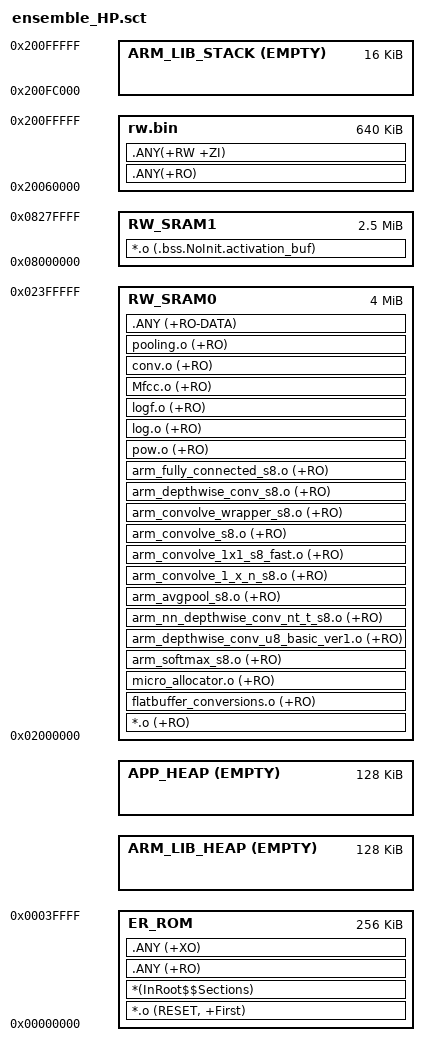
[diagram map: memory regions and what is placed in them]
#! armclang -E --target=arm-arm-none-eabi -mcpu=cortex-m55 -xc
; command above MUST be in first line (no comment above!)
/*
;-------- <<< Use Configuration Wizard in Context Menu >>> -------------------
*/

/*--------------------- ITCM Configuration ----------------------------------
; <h> ITCM Configuration
;   <o0> ITCM Base Address <0x0-0xFFFFFFFF:8>
;   <o1> ITCM Size (in Bytes) <0x0-0xFFFFFFFF:8>
; </h>
 *----------------------------------------------------------------------------*/
/* SRAM2 is mapped as ITCM in M55-HP */
#define __ROM_BASE      0x00000000
#define __ROM_SIZE      0x00040000

/*--------------------- DTCM Configuration ---------------------------
; <h> DTCM Configuration
;   <o0> DTCM Base Address    <0x0-0xFFFFFFFF:8>
;   <o1> DTCM Size (in Bytes) <0x0-0xFFFFFFFF:8>
; </h>
 *----------------------------------------------------------------------------*/
/* SRAM3 is mapped as DTCM in M55-HP */
#define __RAM_BASE      0x20000000
#define __RAM_SIZE      0x00100000

/*--------------------- Stack / Heap Configuration ---------------------------
; <h> Stack / Heap Configuration
;   <o0> Stack Size (in Bytes) <0x0-0xFFFFFFFF:8>
;   <o1> Heap Size (in Bytes) <0x0-0xFFFFFFFF:8>
;   <o2> App Heap Size (in Bytes) <0x0-0xFFFFFFFF:8>
; </h>
 *----------------------------------------------------------------------------*/
#define __STACK_SIZE    0x00004000
#define __HEAP_SIZE     0x00020000
#define __APP_HEAP_SIZE 0x00020000

/*
;------------- <<< end of configuration section >>> ---------------------------
*/


/*----------------------------------------------------------------------------
   User Stack & Heap boundary definition
   *----------------------------------------------------------------------------*/
#define __STACK_TOP     (__RAM_BASE + __RAM_SIZE)    /* starts at end of RAM */
#define __HEAP_BASE     (AlignExpr(+0, 8))           /* starts after RW_RAM section, 8 byte aligned */
#define __APP_HEAP_BASE (AlignExpr(+0, 8)) 	     /* starts after HEAP, 8 byte aligned */


/*----------------------------------------------------------------------------
  Scatter File Definitions definition
 *----------------------------------------------------------------------------*/
#define __RO_BASE       __ROM_BASE
#define __RO_SIZE       __ROM_SIZE

#define __RW_BASE       __RAM_BASE
#define __RW_SIZE      (__RAM_SIZE - __STACK_SIZE - __HEAP_SIZE - __APP_HEAP_SIZE)


LR_ROM __RO_BASE __RO_SIZE  {                       ; load region size_region
  ER_ROM __RO_BASE __RO_SIZE  {                     ; load address = execution address
   *.o (RESET, +First)
   *(InRoot$$Sections)
   .ANY (+RO)
   .ANY (+XO)
  }


#if __HEAP_SIZE > 0
  ARM_LIB_HEAP  __HEAP_BASE EMPTY  __HEAP_SIZE  {   ; Reserve empty region for heap
  }
#endif

  APP_HEAP  __APP_HEAP_BASE EMPTY  __APP_HEAP_SIZE {; Reserve empty region for application heap
  }



  ARM_LIB_STACK __STACK_TOP EMPTY -__STACK_SIZE {   ; Reserve empty region for stack
  }
}

 LOAD_REGION_1       0x02000000                  0x00400000
{ 
  RW_SRAM0 0x02000000 0x00400000  {  ; Update sections as needed
          ; nn model's baked in input matrices
        ;*.o (ifm)

        ; nn model
        ;*.o (nn_model)

        ; if the activation buffer (tensor arena) doesn't
        ; fit in the SRAM region, we accommodate it here
        ;*.o (activation_buf)

        *.o (+RO)

        ; Flatbuffer conversion related code
        flatbuffer_conversions.o (+RO)

        ; micro allocator related code
        micro_allocator.o (+RO)

        arm_softmax_s8.o (+RO)
        arm_depthwise_conv_u8_basic_ver1.o (+RO)
        arm_nn_depthwise_conv_nt_t_s8.o (+RO)
        arm_avgpool_s8.o (+RO)
        arm_convolve_1_x_n_s8.o (+RO)
        arm_convolve_1x1_s8_fast.o (+RO)
        arm_convolve_s8.o (+RO)
        arm_convolve_wrapper_s8.o (+RO)
        arm_depthwise_conv_s8.o (+RO)
        arm_fully_connected_s8.o (+RO)
        pow.o (+RO)
        log.o (+RO)
        logf.o (+RO)
        Mfcc.o (+RO)
        conv.o (+RO)
        pooling.o (+RO)

        

        ; RO data (incl. unwinding tables for debugging)
        .ANY (+RO-DATA)

  }
  RW_SRAM1 0x08000000 0x00280000  {  ; Update sections as needed

          ; activation buffers a.k.a tensor arena
        *.o (.bss.NoInit.activation_buf)

  }

      ;-----------------------------------------------------
    ; R/W region - ramaining part of the 1MiB RAM region
    ; Other parts of this region used up by stack + heap.
    ;-----------------------------------------------------
    rw.bin        0x20060000     (0x00100000 - 0x00060000)
    {
        .ANY(+RO)
        .ANY(+RW +ZI)
    }

}
